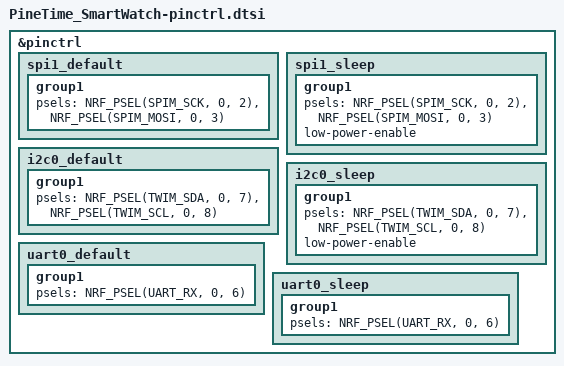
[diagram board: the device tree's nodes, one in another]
&pinctrl {
    spi1_default: spi1_default {
		group1 {
				psels = <NRF_PSEL(SPIM_SCK, 0, 2)>,
						<NRF_PSEL(SPIM_MOSI, 0, 3)>;
		};
	};
	spi1_sleep: spi1_sleep {
		group1 {
				psels = <NRF_PSEL(SPIM_SCK, 0, 2)>,
						<NRF_PSEL(SPIM_MOSI, 0, 3)>;
				low-power-enable;
		};
	};
    i2c0_default: i2c0_default {
		group1 {
			psels = <NRF_PSEL(TWIM_SDA, 0, 7)>,
				<NRF_PSEL(TWIM_SCL, 0, 8)>;
		};
	};

	i2c0_sleep: i2c0_sleep {
		group1 {
			psels = <NRF_PSEL(TWIM_SDA, 0, 7)>,
				<NRF_PSEL(TWIM_SCL, 0, 8)>;
			low-power-enable;
		};
	};
	uart0_default: uart0_default {
        group1 {
            psels = <NRF_PSEL(UART_TX, 0, 8)>; // P0.22
			psels = <NRF_PSEL(UART_RX, 0, 6)>; // P0.21
        };
    };

    uart0_sleep: uart0_sleep {
        group1 {
            psels = <NRF_PSEL(UART_TX, 0, 8)>;
			psels = <NRF_PSEL(UART_RX, 0, 6)>;
        };
    };


};


